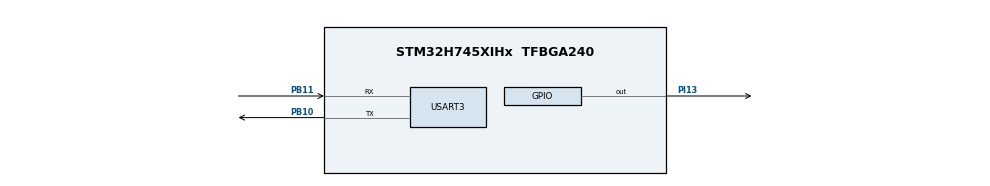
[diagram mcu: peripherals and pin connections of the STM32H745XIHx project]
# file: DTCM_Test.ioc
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CORTEX_M7.CPU_DCache=Enabled
CORTEX_M7.CPU_ICache=Enabled
CortexM4.IPs=FATFS_M4\:I,FREERTOS_M4\:I,IWDG2\:I,RCC,USB_DEVICE_M4\:I,USB_HOST_M4\:I,WWDG2\:I,DMA,BDMA,MDMA,NVIC2\:I,ETH\:I,FDCAN1\:I,FDCAN2\:I,FMC\:I,QUADSPI\:I,SAI2\:I,SDMMC1\:I,LTDC\:I,USB_OTG_FS\:I,SAI4\:I,DEBUG,PDM2PCM_M4\:I,PWR,RESMGR_UTILITY,SYS_M4\:I,CORTEX_M4\:I,OPENAMP_M4\:I,VREFBUF,GPIO
CortexM7.IPs=FATFS_M7\:I,FREERTOS_M7\:I,IWDG1\:I,RCC\:I,USB_DEVICE_M7\:I,USB_HOST_M7\:I,WWDG1\:I,DMA\:I,BDMA\:I,MDMA\:I,NVIC1\:I,CORTEX_M7\:I,DEBUG\:I,PDM2PCM_M7\:I,PWR\:I,RESMGR_UTILITY\:I,SYS\:I,OPENAMP_M7\:I,VREFBUF\:I,GPIO\:I,USART3\:I
CortexM7.Pins=PI13
Mcu.Family=STM32H7
Mcu.Name=STM32H745XIHx
Mcu.Package=TFBGA240
NVIC1.PriorityGroup=NVIC_PRIORITYGROUP_4
NVIC2.PriorityGroup=NVIC_PRIORITYGROUP_4
PB10.Mode=Asynchronous
PB10.PinAttribute=CortexM7
PB10.Signal=USART3_TX
PB11.Mode=Asynchronous
PB11.PinAttribute=CortexM7
PB11.Signal=USART3_RX
PH0-OSC_IN\ (PH0).Mode=HSE-External-Clock-Source
PH0-OSC_IN\ (PH0).PinAttribute=Free
PH0-OSC_IN\ (PH0).Signal=RCC_OSC_IN
PI13.PinAttribute=CortexM7
PI13.Signal=GPIO_Output
ProjectManager.HeapSize=M4-0x200,M7-0x200
ProjectManager.StackSize=M4-0x400,M7-0x400
ProjectManager.TargetToolchain=STM32CubeIDE
RCC.ADCFreq_Value=50390625
RCC.APB1Freq_Value=100000000
RCC.APB2Freq_Value=100000000
RCC.APB3Freq_Value=100000000
RCC.APB4Freq_Value=100000000
RCC.CortexFreq_Value=400000000
RCC.D1PPRE=RCC_APB3_DIV2
RCC.D2PPRE1=RCC_APB1_DIV2
RCC.D2PPRE2=RCC_APB2_DIV2
RCC.D3PPRE=RCC_APB4_DIV2
RCC.DIVM1=2
RCC.DIVN1=64
RCC.DIVN3=192
RCC.DIVQ1=4
RCC.DIVR1=4
RCC.HCLKFreq_Value=200000000
RCC.HPRE=RCC_HCLK_DIV2
RCC.PLL2FRACN=0
RCC.PLL3FRACN=0
RCC.PLLFRACN=0
RCC.PLLSourceVirtual=RCC_PLLSOURCE_HSE
RCC.PWR_Regulator_Voltage_Scale=PWR_REGULATOR_VOLTAGE_SCALE1
RCC.SYSCLKFreq_VALUE=400000000
RCC.SYSCLKSource=RCC_SYSCLKSOURCE_PLLCLK
RCC.SupplySource=PWR_DIRECT_SMPS_SUPPLY
RCC.USBFreq_Value=200000000
USART3.VirtualMode-Asynchronous=VM_ASYNC
VP_SYS_M4_VS_Systick.Mode=SysTick
board=STM32H745I-DISCO

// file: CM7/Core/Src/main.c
/* USER CODE BEGIN Header */
/**
  ******************************************************************************
  * @file           : main.c
  * @brief          : Main program body
  ******************************************************************************
  * @attention
  *
  * Copyright (c) 2025 STMicroelectronics.
  * All rights reserved.
  *
  * This software is licensed under terms that can be found in the LICENSE file
  * in the root directory of this software component.
  * If no LICENSE file comes with this software, it is provided AS-IS.
  *
  ******************************************************************************
  */
/* USER CODE END Header */
#include "main.h"

/* USER CODE BEGIN PD */

#ifndef HSEM_ID_0
#define HSEM_ID_0 (0U) /* HW semaphore 0*/
#endif

#define DATA_SIZE 4096

/* USER CODE END PD */

UART_HandleTypeDef huart3;

/* USER CODE BEGIN PV */
unsigned char str1[50];
unsigned char str2[50];

int32_t sram_data[DATA_SIZE];

__attribute__((section(".dtcm_data")))
int32_t dtcm_data[DATA_SIZE];

/* USER CODE END PV */

void SystemClock_Config(void);
static void MX_GPIO_Init(void);
static void MX_USART3_UART_Init(void);

/* USER CODE BEGIN 0 */
void Puts_Serial(char *str)
{
	while(*str!=0)
	{
	HAL_UART_Transmit(&huart3,(unsigned char *)str,1,10);
	str++;
	}
}

void init_buffers(void)
{
    for (int i = 0; i < DATA_SIZE; i++)
    {
        sram_data[i] = i + 1;
        dtcm_data[i] = i + 1;
    }
}

__attribute__((noinline))
int32_t compute_on_buffer(int32_t *buf, uint32_t len, uint32_t rounds)
{
    volatile int32_t acc = 0;

    for (uint32_t r = 0; r < rounds; r++)
    {
        for (uint32_t i = 0; i < len; i++)
        {
            acc += buf[i] * 3;
            acc ^= (acc << 1);
        }
    }
    return acc;
}

static inline void dwt_init(void)
{
    CoreDebug->DEMCR |= CoreDebug_DEMCR_TRCENA_Msk;
    DWT->CYCCNT = 0;
    DWT->CTRL |= DWT_CTRL_CYCCNTENA_Msk;
}

static inline uint32_t dwt_get(void)
{
    return DWT->CYCCNT;
}
/* USER CODE END 0 */

int main(void)
{

/* USER CODE BEGIN Boot_Mode_Sequence_0 */
  //int32_t timeout;
/* USER CODE END Boot_Mode_Sequence_0 */

  /* Enable the CPU Cache */

  /* Enable I-Cache---------------------------------------------------------*/
  SCB_EnableICache();

  /* Enable D-Cache---------------------------------------------------------*/
  SCB_EnableDCache();

/* USER CODE BEGIN Boot_Mode_Sequence_1 */
  /* Wait until CPU2 boots and enters in stop mode or timeout*/
  /*timeout = 0xFFFF;
  while((__HAL_RCC_GET_FLAG(RCC_FLAG_D2CKRDY) != RESET) && (timeout-- > 0));
  if ( timeout < 0 )
  {
  Error_Handler();
  }*/
/* USER CODE END Boot_Mode_Sequence_1 */
  /* MCU Configuration--------------------------------------------------------*/

  /* Reset of all peripherals, Initializes the Flash interface and the Systick. */
  HAL_Init();

  /* Configure the system clock */
  SystemClock_Config();
/* USER CODE BEGIN Boot_Mode_Sequence_2 */
/* When system initialization is finished, Cortex-M7 will release Cortex-M4 by means of
HSEM notification */
/*HW semaphore Clock enable*/
__HAL_RCC_HSEM_CLK_ENABLE();
/*Take HSEM */
HAL_HSEM_FastTake(HSEM_ID_0);
/*Release HSEM in order to notify the CPU2(CM4)*/
HAL_HSEM_Release(HSEM_ID_0,0);
/* wait until CPU2 wakes up from stop mode */
/*timeout = 0xFFFF;
while((__HAL_RCC_GET_FLAG(RCC_FLAG_D2CKRDY) == RESET) && (timeout-- > 0));
if ( timeout < 0 )
{
Error_Handler();
}*/
/* USER CODE END Boot_Mode_Sequence_2 */

  /* Initialize all configured peripherals */
  MX_GPIO_Init();
  MX_USART3_UART_Init();
  /* USER CODE BEGIN 2 */

  volatile int32_t res1, res2;
  uint32_t t0, t1;
  uint32_t cycles_sram, cycles_dtcm;

  init_buffers();
  dwt_init();

  /* ---- SRAM test ---- */
  DWT->CYCCNT = 0;
  t0 = dwt_get();
  res1 = compute_on_buffer(sram_data, DATA_SIZE, 1000);
  t1 = dwt_get();
  cycles_sram = t1 - t0;

  /* ---- DTCM test ---- */
  DWT->CYCCNT = 0;
  t0 = dwt_get();
  res2 = compute_on_buffer(dtcm_data, DATA_SIZE, 1000);
  t1 = dwt_get();
  cycles_dtcm = t1 - t0;

  sprintf(str1,"SRAM cycles: %lu\r\n", cycles_sram);
  sprintf(str2,"DTCM cycles: %lu\r\n", cycles_dtcm);

  Puts_Serial(str1);
  Puts_Serial(str2);

  /* USER CODE END 2 */

  /* Infinite loop */
  while (1)
  {

  }
}

void SystemClock_Config(void)
{
  RCC_OscInitTypeDef RCC_OscInitStruct = {0};
  RCC_ClkInitTypeDef RCC_ClkInitStruct = {0};

  /** Supply configuration update enable
  */
  HAL_PWREx_ConfigSupply(PWR_DIRECT_SMPS_SUPPLY);

  /** Configure the main internal regulator output voltage
  */
  __HAL_PWR_VOLTAGESCALING_CONFIG(PWR_REGULATOR_VOLTAGE_SCALE1);

  while(!__HAL_PWR_GET_FLAG(PWR_FLAG_VOSRDY)) {}

  /** Initializes the RCC Oscillators according to the specified parameters
  * in the RCC_OscInitTypeDef structure.
  */
  RCC_OscInitStruct.OscillatorType = RCC_OSCILLATORTYPE_HSE;
  RCC_OscInitStruct.HSEState = RCC_HSE_BYPASS;
  RCC_OscInitStruct.PLL.PLLState = RCC_PLL_ON;
  RCC_OscInitStruct.PLL.PLLSource = RCC_PLLSOURCE_HSE;
  RCC_OscInitStruct.PLL.PLLM = 2;
  RCC_OscInitStruct.PLL.PLLN = 64;
  RCC_OscInitStruct.PLL.PLLP = 2;
  RCC_OscInitStruct.PLL.PLLQ = 4;
  RCC_OscInitStruct.PLL.PLLR = 4;
  RCC_OscInitStruct.PLL.PLLRGE = RCC_PLL1VCIRANGE_3;
  RCC_OscInitStruct.PLL.PLLVCOSEL = RCC_PLL1VCOWIDE;
  RCC_OscInitStruct.PLL.PLLFRACN = 0;
  if (HAL_RCC_OscConfig(&RCC_OscInitStruct) != HAL_OK)
  {
    Error_Handler();
  }

  /** Initializes the CPU, AHB and APB buses clocks
  */
  RCC_ClkInitStruct.ClockType = RCC_CLOCKTYPE_HCLK|RCC_CLOCKTYPE_SYSCLK
                              |RCC_CLOCKTYPE_PCLK1|RCC_CLOCKTYPE_PCLK2
                              |RCC_CLOCKTYPE_D3PCLK1|RCC_CLOCKTYPE_D1PCLK1;
  RCC_ClkInitStruct.SYSCLKSource = RCC_SYSCLKSOURCE_PLLCLK;
  RCC_ClkInitStruct.SYSCLKDivider = RCC_SYSCLK_DIV1;
  RCC_ClkInitStruct.AHBCLKDivider = RCC_HCLK_DIV2;
  RCC_ClkInitStruct.APB3CLKDivider = RCC_APB3_DIV2;
  RCC_ClkInitStruct.APB1CLKDivider = RCC_APB1_DIV2;
  RCC_ClkInitStruct.APB2CLKDivider = RCC_APB2_DIV2;
  RCC_ClkInitStruct.APB4CLKDivider = RCC_APB4_DIV2;

  if (HAL_RCC_ClockConfig(&RCC_ClkInitStruct, FLASH_LATENCY_2) != HAL_OK)
  {
    Error_Handler();
  }
}

static void MX_USART3_UART_Init(void)
{

  huart3.Instance = USART3;
  huart3.Init.BaudRate = 115200;
  huart3.Init.WordLength = UART_WORDLENGTH_8B;
  huart3.Init.StopBits = UART_STOPBITS_1;
  huart3.Init.Parity = UART_PARITY_NONE;
  huart3.Init.Mode = UART_MODE_TX_RX;
  huart3.Init.HwFlowCtl = UART_HWCONTROL_NONE;
  huart3.Init.OverSampling = UART_OVERSAMPLING_16;
  huart3.Init.OneBitSampling = UART_ONE_BIT_SAMPLE_DISABLE;
  huart3.Init.ClockPrescaler = UART_PRESCALER_DIV1;
  huart3.AdvancedInit.AdvFeatureInit = UART_ADVFEATURE_NO_INIT;
  if (HAL_UART_Init(&huart3) != HAL_OK)
  {
    Error_Handler();
  }
  if (HAL_UARTEx_SetTxFifoThreshold(&huart3, UART_TXFIFO_THRESHOLD_1_8) != HAL_OK)
  {
    Error_Handler();
  }
  if (HAL_UARTEx_SetRxFifoThreshold(&huart3, UART_RXFIFO_THRESHOLD_1_8) != HAL_OK)
  {
    Error_Handler();
  }
  if (HAL_UARTEx_DisableFifoMode(&huart3) != HAL_OK)
  {
    Error_Handler();
  }

}

static void MX_GPIO_Init(void)
{
  GPIO_InitTypeDef GPIO_InitStruct = {0};

  /* GPIO Ports Clock Enable */
  __HAL_RCC_GPIOI_CLK_ENABLE();
  __HAL_RCC_GPIOB_CLK_ENABLE();

  /*Configure GPIO pin Output Level */
  HAL_GPIO_WritePin(GPIOI, GPIO_PIN_13, GPIO_PIN_RESET);

  /*Configure GPIO pin : PI13 */
  GPIO_InitStruct.Pin = GPIO_PIN_13;
  GPIO_InitStruct.Mode = GPIO_MODE_OUTPUT_PP;
  GPIO_InitStruct.Pull = GPIO_NOPULL;
  GPIO_InitStruct.Speed = GPIO_SPEED_FREQ_LOW;
  HAL_GPIO_Init(GPIOI, &GPIO_InitStruct);

}

void Error_Handler(void)
{
  __disable_irq();
  while (1)
  {
  }
}
